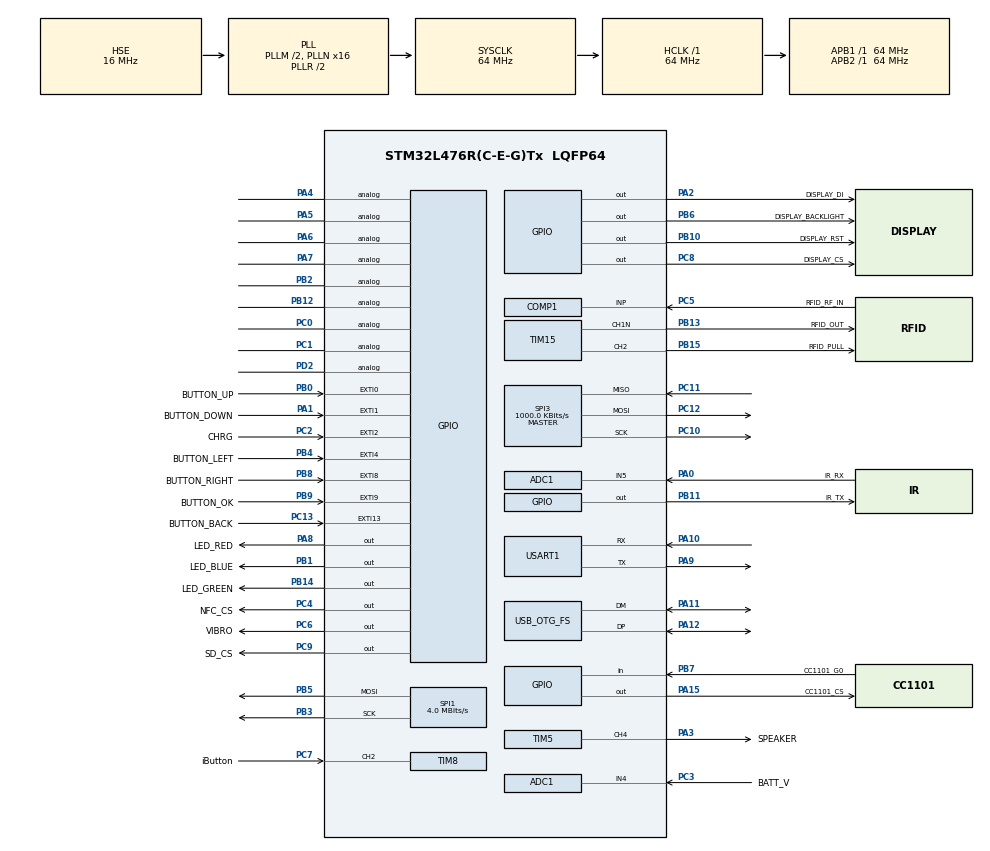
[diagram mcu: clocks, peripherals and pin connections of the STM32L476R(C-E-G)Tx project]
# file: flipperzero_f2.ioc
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ADC1.Channel-0\#ChannelRegularConversion=ADC_CHANNEL_4
ADC1.NbrOfConversion=1
ADC1.NbrOfConversionFlag=1
ADC1.OffsetNumber-0\#ChannelRegularConversion=ADC_OFFSET_NONE
ADC1.Rank-0\#ChannelRegularConversion=1
ADC1.SamplingTime-0\#ChannelRegularConversion=ADC_SAMPLETIME_2CYCLES_5
ADC1.master=1
FREERTOS.HEAP_NUMBER=1
FREERTOS.Tasks01=defaultTask,0,1024,StartDefaultTask,Default,NULL,Dynamic,NULL,NULL
FREERTOS.configTOTAL_HEAP_SIZE=8192
FREERTOS.configUSE_IDLE_HOOK=1
FREERTOS.configUSE_TIMERS=1
Mcu.Family=STM32L4
Mcu.Name=STM32L476R(C-E-G)Tx
Mcu.Package=LQFP64
NVIC.EXTI0_IRQn=true\:5\:0\:false\:false\:true\:true\:true\:true
NVIC.EXTI15_10_IRQn=true\:5\:0\:true\:false\:true\:false\:true\:true
NVIC.EXTI1_IRQn=true\:5\:0\:false\:false\:true\:true\:true\:true
NVIC.EXTI2_IRQn=true\:5\:0\:false\:false\:true\:true\:true\:true
NVIC.EXTI4_IRQn=true\:5\:0\:false\:false\:true\:true\:true\:true
NVIC.EXTI9_5_IRQn=true\:5\:0\:false\:false\:true\:true\:true\:true
NVIC.OTG_FS_IRQn=true\:5\:0\:false\:false\:true\:true\:false\:true
NVIC.PriorityGroup=NVIC_PRIORITYGROUP_4
NVIC.TIM8_CC_IRQn=true\:5\:0\:false\:false\:true\:true\:true\:true
PA0.GPIO_Label=IR_RX
PA0.Signal=ADCx_IN5
PA1.GPIO_Label=BUTTON_DOWN
PA1.GPIO_ModeDefaultEXTI=GPIO_MODE_IT_RISING_FALLING
PA1.GPIO_PuPd=GPIO_PULLDOWN
PA1.Signal=GPXTI1
PA10.Mode=Asynchronous
PA10.Signal=USART1_RX
PA11.Mode=Device_Only
PA11.Signal=USB_OTG_FS_DM
PA12.Mode=Device_Only
PA12.Signal=USB_OTG_FS_DP
PA13\ (JTMS-SWDIO).GPIO_Label=TMS
PA13\ (JTMS-SWDIO).Mode=Serial_Wire
PA13\ (JTMS-SWDIO).Signal=SYS_JTMS-SWDIO
PA14\ (JTCK-SWCLK).GPIO_Label=TCK
PA14\ (JTCK-SWCLK).Mode=Serial_Wire
PA14\ (JTCK-SWCLK).Signal=SYS_JTCK-SWCLK
PA15\ (JTDI).GPIO_Label=CC1101_CS
PA15\ (JTDI).Signal=GPIO_Output
PA2.GPIO_Label=DISPLAY_DI
PA2.Signal=GPIO_Output
PA3.GPIO_Label=SPEAKER
PA3.Signal=S_TIM5_CH4
PA4.Signal=GPIO_Analog
PA5.Signal=GPIO_Analog
PA6.Signal=GPIO_Analog
PA7.Signal=GPIO_Analog
PA8.GPIO_Label=LED_RED
PA8.GPIO_ModeDefaultOutputPP=GPIO_MODE_OUTPUT_OD
PA8.GPIO_Speed=GPIO_SPEED_FREQ_HIGH
PA8.PinState=GPIO_PIN_SET
PA8.Signal=GPIO_Output
PA9.Mode=Asynchronous
PA9.Signal=USART1_TX
PB0.GPIO_Label=BUTTON_UP
PB0.GPIO_ModeDefaultEXTI=GPIO_MODE_IT_RISING_FALLING
PB0.GPIO_PuPd=GPIO_PULLDOWN
PB0.Signal=GPXTI0
PB1.GPIO_Label=LED_BLUE
PB1.GPIO_ModeDefaultOutputPP=GPIO_MODE_OUTPUT_OD
PB1.GPIO_Speed=GPIO_SPEED_FREQ_MEDIUM
PB1.PinState=GPIO_PIN_SET
PB1.Signal=GPIO_Output
PB10.GPIO_Label=DISPLAY_RST
PB10.Signal=GPIO_Output
PB11.GPIO_Label=IR_TX
PB11.Signal=GPIO_Output
PB12.Signal=GPIO_Analog
PB13.GPIO_Label=RFID_OUT
PB13.Mode=Output Compare1 CH1N
PB13.Signal=TIM15_CH1N
PB14.GPIO_Label=LED_GREEN
PB14.GPIO_ModeDefaultOutputPP=GPIO_MODE_OUTPUT_OD
PB14.GPIO_Speed=GPIO_SPEED_FREQ_MEDIUM
PB14.PinState=GPIO_PIN_SET
PB14.Signal=GPIO_Output
PB15.GPIO_Label=RFID_PULL
PB15.Signal=S_TIM15_CH2
PB2.Signal=GPIO_Analog
PB3\ (JTDO-TRACESWO).Mode=TX_Only_Simplex_Unidirect_Master
PB3\ (JTDO-TRACESWO).Signal=SPI1_SCK
PB4\ (NJTRST).GPIO_Label=BUTTON_LEFT
PB4\ (NJTRST).GPIO_ModeDefaultEXTI=GPIO_MODE_IT_RISING_FALLING
PB4\ (NJTRST).GPIO_PuPd=GPIO_PULLDOWN
PB4\ (NJTRST).Signal=GPXTI4
PB5.Mode=TX_Only_Simplex_Unidirect_Master
PB5.Signal=SPI1_MOSI
PB6.GPIO_Label=DISPLAY_BACKLIGHT
PB6.GPIO_Speed=GPIO_SPEED_FREQ_LOW
PB6.Signal=GPIO_Output
PB7.GPIO_Label=CC1101_G0
PB7.Signal=GPIO_Input
PB8.GPIO_Label=BUTTON_RIGHT
PB8.GPIO_ModeDefaultEXTI=GPIO_MODE_IT_RISING_FALLING
PB8.GPIO_PuPd=GPIO_PULLDOWN
PB8.Signal=GPXTI8
PB9.GPIO_Label=BUTTON_OK
PB9.GPIO_ModeDefaultEXTI=GPIO_MODE_IT_RISING_FALLING
PB9.GPIO_PuPd=GPIO_PULLDOWN
PB9.Signal=GPXTI9
PC0.Signal=GPIO_Analog
PC1.Signal=GPIO_Analog
PC10.Mode=Full_Duplex_Master
PC10.Signal=SPI3_SCK
PC11.Mode=Full_Duplex_Master
PC11.Signal=SPI3_MISO
PC12.Mode=Full_Duplex_Master
PC12.Signal=SPI3_MOSI
PC13.GPIO_Label=BUTTON_BACK
PC13.GPIO_ModeDefaultEXTI=GPIO_MODE_IT_RISING_FALLING
PC13.GPIO_PuPd=GPIO_PULLDOWN
PC13.Signal=GPXTI13
PC14-OSC32_IN\ (PC14).Mode=LSE-External-Oscillator
PC14-OSC32_IN\ (PC14).Signal=RCC_OSC32_IN
PC15-OSC32_OUT\ (PC15).Mode=LSE-External-Oscillator
PC15-OSC32_OUT\ (PC15).Signal=RCC_OSC32_OUT
PC2.GPIO_Label=CHRG
PC2.GPIO_ModeDefaultEXTI=GPIO_MODE_IT_RISING_FALLING
PC2.GPIO_PuPd=GPIO_PULLUP
PC2.Signal=GPXTI2
PC3.GPIO_Label=BATT_V
PC3.Signal=ADCx_IN4
PC4.GPIO_Label=NFC_CS
PC4.Signal=GPIO_Output
PC5.GPIO_Label=RFID_RF_IN
PC5.Mode=INP
PC5.Signal=COMP1_INP
PC6.GPIO_Label=VIBRO
PC6.Signal=GPIO_Output
PC7.GPIO_Label=iButton
PC7.GPIO_ModeDefaultPP=GPIO_MODE_AF_OD
PC7.GPIO_PuPd=GPIO_NOPULL
PC7.GPIO_Speed=GPIO_SPEED_FREQ_MEDIUM
PC7.Signal=S_TIM8_CH2
PC8.GPIO_Label=DISPLAY_CS
PC8.Signal=GPIO_Output
PC9.GPIO_Label=SD_CS
PC9.Signal=GPIO_Output
PD2.Signal=GPIO_Analog
PH0-OSC_IN\ (PH0).Mode=HSE-External-Oscillator
PH0-OSC_IN\ (PH0).Signal=RCC_OSC_IN
PH1-OSC_OUT\ (PH1).Mode=HSE-External-Oscillator
PH1-OSC_OUT\ (PH1).Signal=RCC_OSC_OUT
ProjectManager.HeapSize=0x200
ProjectManager.StackSize=0x400
ProjectManager.TargetToolchain=Makefile
RCC.ADCCLockSelection=RCC_ADCCLKSOURCE_SYSCLK
RCC.ADCFreq_Value=64000000
RCC.AHBFreq_Value=64000000
RCC.APB1Freq_Value=64000000
RCC.APB1TimFreq_Value=64000000
RCC.APB2Freq_Value=64000000
RCC.APB2TimFreq_Value=64000000
RCC.CortexFreq_Value=64000000
RCC.HCLKFreq_Value=64000000
RCC.HSE_VALUE=16000000
RCC.HSI_VALUE=16000000
RCC.MSI_VALUE=4000000
RCC.PLLM=2
RCC.PLLN=16
RCC.PLLSAI1N=12
RCC.PLLSourceVirtual=RCC_PLLSOURCE_HSE
RCC.PREFETCH_ENABLE=1
RCC.SYSCLKFreq_VALUE=64000000
RCC.SYSCLKSource=RCC_SYSCLKSOURCE_PLLCLK
RCC.USBFreq_Value=48000000
RCC.VCOOutputFreq_Value=128000000
SH.ADCx_IN4.0=ADC1_IN4,IN4-Single-Ended
SH.ADCx_IN5.0=ADC1_IN5,IN5-Single-Ended
SH.S_TIM15_CH2.0=TIM15_CH2,Output Compare2 CH2
SH.S_TIM5_CH4.0=TIM5_CH4,PWM Generation4 CH4
SH.S_TIM8_CH2.0=TIM8_CH2,Input_Capture2_from_TI2
SPI1.BaudRatePrescaler=SPI_BAUDRATEPRESCALER_16
SPI1.CLKPhase=SPI_PHASE_1EDGE
SPI1.CLKPolarity=SPI_POLARITY_LOW
SPI1.CalculateBaudRate=4.0 MBits/s
SPI1.DataSize=SPI_DATASIZE_8BIT
SPI1.Direction=SPI_DIRECTION_2LINES
SPI1.Mode=SPI_MODE_MASTER
SPI1.VirtualType=VM_MASTER
SPI3.BaudRatePrescaler=SPI_BAUDRATEPRESCALER_64
SPI3.CLKPolarity=SPI_POLARITY_LOW
SPI3.CalculateBaudRate=1000.0 KBits/s
SPI3.DataSize=SPI_DATASIZE_8BIT
SPI3.Direction=SPI_DIRECTION_2LINES
SPI3.Mode=SPI_MODE_MASTER
SPI3.VirtualType=VM_MASTER
TIM15.Channel-Output\ Compare1\ CH1N=TIM_CHANNEL_1
TIM15.Channel-Output\ Compare2\ CH2=TIM_CHANNEL_2
TIM5.Channel-PWM\ Generation4\ CH4=TIM_CHANNEL_4
TIM5.Period=291
TIM5.Prescaler=500 - 1
TIM5.Pulse-PWM\ Generation4\ CH4=145
TIM8.Channel-Input_Capture2_from_TI2=TIM_CHANNEL_2
TIM8.ICPolarity_CH2=TIM_INPUTCHANNELPOLARITY_BOTHEDGE
TIM8.Period=32768-1
TIM8.Prescaler=64-1
USART1.VirtualMode-Asynchronous=VM_ASYNC
USB_DEVICE.CLASS_NAME_FS=CDC
USB_DEVICE.VirtualMode=Cdc
USB_DEVICE.VirtualModeFS=Cdc_FS
USB_OTG_FS.VirtualMode=Device_Only
VP_ADC1_TempSens_Input.Mode=IN-TempSens
VP_ADC1_Vref_Input.Mode=IN-Vrefint
VP_COMP1_VS_VREFINT12.Mode=VREFINT_12
VP_FREERTOS_VS_CMSIS_V1.Mode=CMSIS_V1
VP_TIM8_VS_ClockSourceINT.Mode=Internal
VP_USB_DEVICE_VS_USB_DEVICE_CDC_FS.Mode=CDC_FS
board=NUCLEO-L476RG

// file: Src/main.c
/* USER CODE BEGIN Header */
/**
  ******************************************************************************
  * @file           : main.c
  * @brief          : Main program body
  ******************************************************************************
  * @attention
  *
  * <h2><center>&copy; Copyright (c) 2020 STMicroelectronics.
  * All rights reserved.</center></h2>
  *
  * This software component is licensed by ST under Ultimate Liberty license
  * SLA0044, the "License"; You may not use this file except in compliance with
  * the License. You may obtain a copy of the License at:
  *                             www.st.com/SLA0044
  *
  ******************************************************************************
  */
/* USER CODE END Header */

#include "main.h"
#include "boot.h"
#include "cmsis_os.h"
#include "usb_device.h"

ADC_HandleTypeDef hadc1;

COMP_HandleTypeDef hcomp1;

SPI_HandleTypeDef hspi1;
SPI_HandleTypeDef hspi3;

TIM_HandleTypeDef htim5;
TIM_HandleTypeDef htim8;
TIM_HandleTypeDef htim15;

UART_HandleTypeDef huart1;

osThreadId defaultTaskHandle;

void SystemClock_Config(void);
static void MX_GPIO_Init(void);
static void MX_SPI1_Init(void);
static void MX_SPI3_Init(void);
static void MX_ADC1_Init(void);
static void MX_COMP1_Init(void);
static void MX_TIM5_Init(void);
static void MX_TIM15_Init(void);
static void MX_USART1_UART_Init(void);
static void MX_TIM8_Init(void);
void StartDefaultTask(void const* argument);

int main(void) {

    /* MCU Configuration--------------------------------------------------------*/

    /* Reset of all peripherals, Initializes the Flash interface and the Systick. */
    HAL_Init();

    /* Configure the system clock */
    SystemClock_Config();

    /* Initialize all configured peripherals */
    MX_GPIO_Init();
    MX_SPI1_Init();
    MX_SPI3_Init();
    MX_ADC1_Init();
    MX_COMP1_Init();
    MX_TIM5_Init();
    MX_TIM15_Init();
    MX_USART1_UART_Init();
    MX_TIM8_Init();

    /* Create the thread(s) */
    /* definition and creation of defaultTask */
    osThreadDef(defaultTask, StartDefaultTask, osPriorityNormal, 0, 1024);
    defaultTaskHandle = osThreadCreate(osThread(defaultTask), NULL);

    /* Start scheduler */
    osKernelStart();

    /* We should never get here as control is now taken by the scheduler */

    /* Infinite loop */
    while(1) {

    }
}

void SystemClock_Config(void) {
    RCC_OscInitTypeDef RCC_OscInitStruct = {0};
    RCC_ClkInitTypeDef RCC_ClkInitStruct = {0};
    RCC_PeriphCLKInitTypeDef PeriphClkInit = {0};

    /** Initializes the CPU, AHB and APB busses clocks
  */
    RCC_OscInitStruct.OscillatorType = RCC_OSCILLATORTYPE_HSE;
    RCC_OscInitStruct.HSEState = RCC_HSE_ON;
    RCC_OscInitStruct.PLL.PLLState = RCC_PLL_ON;
    RCC_OscInitStruct.PLL.PLLSource = RCC_PLLSOURCE_HSE;
    RCC_OscInitStruct.PLL.PLLM = 2;
    RCC_OscInitStruct.PLL.PLLN = 16;
    RCC_OscInitStruct.PLL.PLLP = RCC_PLLP_DIV7;
    RCC_OscInitStruct.PLL.PLLQ = RCC_PLLQ_DIV2;
    RCC_OscInitStruct.PLL.PLLR = RCC_PLLR_DIV2;
    if(HAL_RCC_OscConfig(&RCC_OscInitStruct) != HAL_OK) {
        Error_Handler();
    }
    /** Initializes the CPU, AHB and APB busses clocks
  */
    RCC_ClkInitStruct.ClockType = RCC_CLOCKTYPE_HCLK | RCC_CLOCKTYPE_SYSCLK | RCC_CLOCKTYPE_PCLK1 |
                                  RCC_CLOCKTYPE_PCLK2;
    RCC_ClkInitStruct.SYSCLKSource = RCC_SYSCLKSOURCE_PLLCLK;
    RCC_ClkInitStruct.AHBCLKDivider = RCC_SYSCLK_DIV1;
    RCC_ClkInitStruct.APB1CLKDivider = RCC_HCLK_DIV1;
    RCC_ClkInitStruct.APB2CLKDivider = RCC_HCLK_DIV1;

    if(HAL_RCC_ClockConfig(&RCC_ClkInitStruct, FLASH_LATENCY_3) != HAL_OK) {
        Error_Handler();
    }
    PeriphClkInit.PeriphClockSelection = RCC_PERIPHCLK_USART1 | RCC_PERIPHCLK_USB |
                                         RCC_PERIPHCLK_ADC;
    PeriphClkInit.Usart1ClockSelection = RCC_USART1CLKSOURCE_PCLK2;
    PeriphClkInit.AdcClockSelection = RCC_ADCCLKSOURCE_SYSCLK;
    PeriphClkInit.UsbClockSelection = RCC_USBCLKSOURCE_PLLSAI1;
    PeriphClkInit.PLLSAI1.PLLSAI1Source = RCC_PLLSOURCE_HSE;
    PeriphClkInit.PLLSAI1.PLLSAI1M = 2;
    PeriphClkInit.PLLSAI1.PLLSAI1N = 12;
    PeriphClkInit.PLLSAI1.PLLSAI1P = RCC_PLLP_DIV7;
    PeriphClkInit.PLLSAI1.PLLSAI1Q = RCC_PLLQ_DIV2;
    PeriphClkInit.PLLSAI1.PLLSAI1R = RCC_PLLR_DIV2;
    PeriphClkInit.PLLSAI1.PLLSAI1ClockOut = RCC_PLLSAI1_48M2CLK;
    if(HAL_RCCEx_PeriphCLKConfig(&PeriphClkInit) != HAL_OK) {
        Error_Handler();
    }
    /** Configure the main internal regulator output voltage
  */
    if(HAL_PWREx_ControlVoltageScaling(PWR_REGULATOR_VOLTAGE_SCALE1) != HAL_OK) {
        Error_Handler();
    }
}

static void MX_ADC1_Init(void) {

    ADC_MultiModeTypeDef multimode = {0};
    ADC_ChannelConfTypeDef sConfig = {0};

    /** Common config
  */
    hadc1.Instance = ADC1;
    hadc1.Init.ClockPrescaler = ADC_CLOCK_ASYNC_DIV1;
    hadc1.Init.Resolution = ADC_RESOLUTION_12B;
    hadc1.Init.DataAlign = ADC_DATAALIGN_RIGHT;
    hadc1.Init.ScanConvMode = ADC_SCAN_DISABLE;
    hadc1.Init.EOCSelection = ADC_EOC_SINGLE_CONV;
    hadc1.Init.LowPowerAutoWait = DISABLE;
    hadc1.Init.ContinuousConvMode = DISABLE;
    hadc1.Init.NbrOfConversion = 1;
    hadc1.Init.DiscontinuousConvMode = DISABLE;
    hadc1.Init.ExternalTrigConv = ADC_SOFTWARE_START;
    hadc1.Init.ExternalTrigConvEdge = ADC_EXTERNALTRIGCONVEDGE_NONE;
    hadc1.Init.DMAContinuousRequests = DISABLE;
    hadc1.Init.Overrun = ADC_OVR_DATA_PRESERVED;
    hadc1.Init.OversamplingMode = DISABLE;
    if(HAL_ADC_Init(&hadc1) != HAL_OK) {
        Error_Handler();
    }
    /** Configure the ADC multi-mode
  */
    multimode.Mode = ADC_MODE_INDEPENDENT;
    if(HAL_ADCEx_MultiModeConfigChannel(&hadc1, &multimode) != HAL_OK) {
        Error_Handler();
    }
    /** Configure Regular Channel
  */
    sConfig.Channel = ADC_CHANNEL_4;
    sConfig.Rank = ADC_REGULAR_RANK_1;
    sConfig.SamplingTime = ADC_SAMPLETIME_2CYCLES_5;
    sConfig.SingleDiff = ADC_SINGLE_ENDED;
    sConfig.OffsetNumber = ADC_OFFSET_NONE;
    sConfig.Offset = 0;
    if(HAL_ADC_ConfigChannel(&hadc1, &sConfig) != HAL_OK) {
        Error_Handler();
    }
}

static void MX_COMP1_Init(void) {

    hcomp1.Instance = COMP1;
    hcomp1.Init.InvertingInput = COMP_INPUT_MINUS_1_2VREFINT;
    hcomp1.Init.NonInvertingInput = COMP_INPUT_PLUS_IO1;
    hcomp1.Init.OutputPol = COMP_OUTPUTPOL_NONINVERTED;
    hcomp1.Init.Hysteresis = COMP_HYSTERESIS_NONE;
    hcomp1.Init.BlankingSrce = COMP_BLANKINGSRC_NONE;
    hcomp1.Init.Mode = COMP_POWERMODE_HIGHSPEED;
    hcomp1.Init.WindowMode = COMP_WINDOWMODE_DISABLE;
    hcomp1.Init.TriggerMode = COMP_TRIGGERMODE_NONE;
    if(HAL_COMP_Init(&hcomp1) != HAL_OK) {
        Error_Handler();
    }
}

static void MX_SPI1_Init(void) {

    /* SPI1 parameter configuration*/
    hspi1.Instance = SPI1;
    hspi1.Init.Mode = SPI_MODE_MASTER;
    hspi1.Init.Direction = SPI_DIRECTION_2LINES;
    hspi1.Init.DataSize = SPI_DATASIZE_8BIT;
    hspi1.Init.CLKPolarity = SPI_POLARITY_LOW;
    hspi1.Init.CLKPhase = SPI_PHASE_1EDGE;
    hspi1.Init.NSS = SPI_NSS_SOFT;
    hspi1.Init.BaudRatePrescaler = SPI_BAUDRATEPRESCALER_16;
    hspi1.Init.FirstBit = SPI_FIRSTBIT_MSB;
    hspi1.Init.TIMode = SPI_TIMODE_DISABLE;
    hspi1.Init.CRCCalculation = SPI_CRCCALCULATION_DISABLE;
    hspi1.Init.CRCPolynomial = 7;
    hspi1.Init.CRCLength = SPI_CRC_LENGTH_DATASIZE;
    hspi1.Init.NSSPMode = SPI_NSS_PULSE_ENABLE;
    if(HAL_SPI_Init(&hspi1) != HAL_OK) {
        Error_Handler();
    }
}

static void MX_SPI3_Init(void) {

    /* SPI3 parameter configuration*/
    hspi3.Instance = SPI3;
    hspi3.Init.Mode = SPI_MODE_MASTER;
    hspi3.Init.Direction = SPI_DIRECTION_2LINES;
    hspi3.Init.DataSize = SPI_DATASIZE_8BIT;
    hspi3.Init.CLKPolarity = SPI_POLARITY_LOW;
    hspi3.Init.CLKPhase = SPI_PHASE_1EDGE;
    hspi3.Init.NSS = SPI_NSS_SOFT;
    hspi3.Init.BaudRatePrescaler = SPI_BAUDRATEPRESCALER_64;
    hspi3.Init.FirstBit = SPI_FIRSTBIT_MSB;
    hspi3.Init.TIMode = SPI_TIMODE_DISABLE;
    hspi3.Init.CRCCalculation = SPI_CRCCALCULATION_DISABLE;
    hspi3.Init.CRCPolynomial = 7;
    hspi3.Init.CRCLength = SPI_CRC_LENGTH_DATASIZE;
    hspi3.Init.NSSPMode = SPI_NSS_PULSE_ENABLE;
    if(HAL_SPI_Init(&hspi3) != HAL_OK) {
        Error_Handler();
    }
}

static void MX_TIM5_Init(void) {

    TIM_MasterConfigTypeDef sMasterConfig = {0};
    TIM_OC_InitTypeDef sConfigOC = {0};

    htim5.Instance = TIM5;
    htim5.Init.Prescaler = 500 - 1;
    htim5.Init.CounterMode = TIM_COUNTERMODE_UP;
    htim5.Init.Period = 291;
    htim5.Init.ClockDivision = TIM_CLOCKDIVISION_DIV1;
    htim5.Init.AutoReloadPreload = TIM_AUTORELOAD_PRELOAD_DISABLE;
    if(HAL_TIM_PWM_Init(&htim5) != HAL_OK) {
        Error_Handler();
    }
    sMasterConfig.MasterOutputTrigger = TIM_TRGO_RESET;
    sMasterConfig.MasterSlaveMode = TIM_MASTERSLAVEMODE_DISABLE;
    if(HAL_TIMEx_MasterConfigSynchronization(&htim5, &sMasterConfig) != HAL_OK) {
        Error_Handler();
    }
    sConfigOC.OCMode = TIM_OCMODE_PWM1;
    sConfigOC.Pulse = 145;
    sConfigOC.OCPolarity = TIM_OCPOLARITY_HIGH;
    sConfigOC.OCFastMode = TIM_OCFAST_DISABLE;
    if(HAL_TIM_PWM_ConfigChannel(&htim5, &sConfigOC, TIM_CHANNEL_4) != HAL_OK) {
        Error_Handler();
    }
    HAL_TIM_MspPostInit(&htim5);
}

static void MX_TIM8_Init(void) {

    TIM_ClockConfigTypeDef sClockSourceConfig = {0};
    TIM_MasterConfigTypeDef sMasterConfig = {0};
    TIM_IC_InitTypeDef sConfigIC = {0};

    htim8.Instance = TIM8;
    htim8.Init.Prescaler = 64 - 1;
    htim8.Init.CounterMode = TIM_COUNTERMODE_UP;
    htim8.Init.Period = 32768 - 1;
    htim8.Init.ClockDivision = TIM_CLOCKDIVISION_DIV1;
    htim8.Init.RepetitionCounter = 0;
    htim8.Init.AutoReloadPreload = TIM_AUTORELOAD_PRELOAD_DISABLE;
    if(HAL_TIM_Base_Init(&htim8) != HAL_OK) {
        Error_Handler();
    }
    sClockSourceConfig.ClockSource = TIM_CLOCKSOURCE_INTERNAL;
    if(HAL_TIM_ConfigClockSource(&htim8, &sClockSourceConfig) != HAL_OK) {
        Error_Handler();
    }
    if(HAL_TIM_IC_Init(&htim8) != HAL_OK) {
        Error_Handler();
    }
    sMasterConfig.MasterOutputTrigger = TIM_TRGO_RESET;
    sMasterConfig.MasterOutputTrigger2 = TIM_TRGO2_RESET;
    sMasterConfig.MasterSlaveMode = TIM_MASTERSLAVEMODE_DISABLE;
    if(HAL_TIMEx_MasterConfigSynchronization(&htim8, &sMasterConfig) != HAL_OK) {
        Error_Handler();
    }
    sConfigIC.ICPolarity = TIM_INPUTCHANNELPOLARITY_BOTHEDGE;
    sConfigIC.ICSelection = TIM_ICSELECTION_DIRECTTI;
    sConfigIC.ICPrescaler = TIM_ICPSC_DIV1;
    sConfigIC.ICFilter = 0;
    if(HAL_TIM_IC_ConfigChannel(&htim8, &sConfigIC, TIM_CHANNEL_2) != HAL_OK) {
        Error_Handler();
    }
}

static void MX_TIM15_Init(void) {

    TIM_MasterConfigTypeDef sMasterConfig = {0};
    TIM_OC_InitTypeDef sConfigOC = {0};
    TIM_BreakDeadTimeConfigTypeDef sBreakDeadTimeConfig = {0};

    htim15.Instance = TIM15;
    htim15.Init.Prescaler = 0;
    htim15.Init.CounterMode = TIM_COUNTERMODE_UP;
    htim15.Init.Period = 0;
    htim15.Init.ClockDivision = TIM_CLOCKDIVISION_DIV1;
    htim15.Init.RepetitionCounter = 0;
    htim15.Init.AutoReloadPreload = TIM_AUTORELOAD_PRELOAD_DISABLE;
    if(HAL_TIM_OC_Init(&htim15) != HAL_OK) {
        Error_Handler();
    }
    sMasterConfig.MasterOutputTrigger = TIM_TRGO_RESET;
    sMasterConfig.MasterSlaveMode = TIM_MASTERSLAVEMODE_DISABLE;
    if(HAL_TIMEx_MasterConfigSynchronization(&htim15, &sMasterConfig) != HAL_OK) {
        Error_Handler();
    }
    sConfigOC.OCMode = TIM_OCMODE_TIMING;
    sConfigOC.Pulse = 0;
    sConfigOC.OCPolarity = TIM_OCPOLARITY_HIGH;
    sConfigOC.OCNPolarity = TIM_OCNPOLARITY_HIGH;
    sConfigOC.OCFastMode = TIM_OCFAST_DISABLE;
    sConfigOC.OCIdleState = TIM_OCIDLESTATE_RESET;
    sConfigOC.OCNIdleState = TIM_OCNIDLESTATE_RESET;
    if(HAL_TIM_OC_ConfigChannel(&htim15, &sConfigOC, TIM_CHANNEL_1) != HAL_OK) {
        Error_Handler();
    }
    if(HAL_TIM_OC_ConfigChannel(&htim15, &sConfigOC, TIM_CHANNEL_2) != HAL_OK) {
        Error_Handler();
    }
    sBreakDeadTimeConfig.OffStateRunMode = TIM_OSSR_DISABLE;
    sBreakDeadTimeConfig.OffStateIDLEMode = TIM_OSSI_DISABLE;
    sBreakDeadTimeConfig.LockLevel = TIM_LOCKLEVEL_OFF;
    sBreakDeadTimeConfig.DeadTime = 0;
    sBreakDeadTimeConfig.BreakState = TIM_BREAK_DISABLE;
    sBreakDeadTimeConfig.BreakPolarity = TIM_BREAKPOLARITY_HIGH;
    sBreakDeadTimeConfig.AutomaticOutput = TIM_AUTOMATICOUTPUT_DISABLE;
    if(HAL_TIMEx_ConfigBreakDeadTime(&htim15, &sBreakDeadTimeConfig) != HAL_OK) {
        Error_Handler();
    }
    HAL_TIM_MspPostInit(&htim15);
}

static void MX_USART1_UART_Init(void) {

    huart1.Instance = USART1;
    huart1.Init.BaudRate = 115200;
    huart1.Init.WordLength = UART_WORDLENGTH_8B;
    huart1.Init.StopBits = UART_STOPBITS_1;
    huart1.Init.Parity = UART_PARITY_NONE;
    huart1.Init.Mode = UART_MODE_TX_RX;
    huart1.Init.HwFlowCtl = UART_HWCONTROL_NONE;
    huart1.Init.OverSampling = UART_OVERSAMPLING_16;
    huart1.Init.OneBitSampling = UART_ONE_BIT_SAMPLE_DISABLE;
    huart1.AdvancedInit.AdvFeatureInit = UART_ADVFEATURE_NO_INIT;
    if(HAL_UART_Init(&huart1) != HAL_OK) {
        Error_Handler();
    }
}

static void MX_GPIO_Init(void) {
    GPIO_InitTypeDef GPIO_InitStruct = {0};

    /* GPIO Ports Clock Enable */
    __HAL_RCC_GPIOC_CLK_ENABLE();
    __HAL_RCC_GPIOH_CLK_ENABLE();
    __HAL_RCC_GPIOA_CLK_ENABLE();
    __HAL_RCC_GPIOB_CLK_ENABLE();
    __HAL_RCC_GPIOD_CLK_ENABLE();

    /*Configure GPIO pin Output Level */
    HAL_GPIO_WritePin(GPIOA, DISPLAY_DI_Pin | CC1101_CS_Pin, GPIO_PIN_RESET);

    /*Configure GPIO pin Output Level */
    HAL_GPIO_WritePin(GPIOC, NFC_CS_Pin | VIBRO_Pin | DISPLAY_CS_Pin | SD_CS_Pin, GPIO_PIN_RESET);

    /*Configure GPIO pin Output Level */
    HAL_GPIO_WritePin(GPIOB, LED_BLUE_Pin | LED_GREEN_Pin, GPIO_PIN_SET);

    /*Configure GPIO pin Output Level */
    HAL_GPIO_WritePin(GPIOB, DISPLAY_RST_Pin | IR_TX_Pin | DISPLAY_BACKLIGHT_Pin, GPIO_PIN_RESET);

    /*Configure GPIO pin Output Level */
    HAL_GPIO_WritePin(LED_RED_GPIO_Port, LED_RED_Pin, GPIO_PIN_SET);

    /*Configure GPIO pin : BUTTON_BACK_Pin */
    GPIO_InitStruct.Pin = BUTTON_BACK_Pin;
    GPIO_InitStruct.Mode = GPIO_MODE_IT_RISING_FALLING;
    GPIO_InitStruct.Pull = GPIO_PULLDOWN;
    HAL_GPIO_Init(BUTTON_BACK_GPIO_Port, &GPIO_InitStruct);

    /*Configure GPIO pins : PC0 PC1 */
    GPIO_InitStruct.Pin = GPIO_PIN_0 | GPIO_PIN_1;
    GPIO_InitStruct.Mode = GPIO_MODE_ANALOG;
    GPIO_InitStruct.Pull = GPIO_NOPULL;
    HAL_GPIO_Init(GPIOC, &GPIO_InitStruct);

    /*Configure GPIO pin : CHRG_Pin */
    GPIO_InitStruct.Pin = CHRG_Pin;
    GPIO_InitStruct.Mode = GPIO_MODE_IT_RISING_FALLING;
    GPIO_InitStruct.Pull = GPIO_PULLUP;
    HAL_GPIO_Init(CHRG_GPIO_Port, &GPIO_InitStruct);

    /*Configure GPIO pin : BUTTON_DOWN_Pin */
    GPIO_InitStruct.Pin = BUTTON_DOWN_Pin;
    GPIO_InitStruct.Mode = GPIO_MODE_IT_RISING_FALLING;
    GPIO_InitStruct.Pull = GPIO_PULLDOWN;
    HAL_GPIO_Init(BUTTON_DOWN_GPIO_Port, &GPIO_InitStruct);

    /*Configure GPIO pins : DISPLAY_DI_Pin CC1101_CS_Pin */
    GPIO_InitStruct.Pin = DISPLAY_DI_Pin | CC1101_CS_Pin;
    GPIO_InitStruct.Mode = GPIO_MODE_OUTPUT_PP;
    GPIO_InitStruct.Pull = GPIO_NOPULL;
    GPIO_InitStruct.Speed = GPIO_SPEED_FREQ_LOW;
    HAL_GPIO_Init(GPIOA, &GPIO_InitStruct);

    /*Configure GPIO pins : PA4 PA5 PA6 PA7 */
    GPIO_InitStruct.Pin = GPIO_PIN_4 | GPIO_PIN_5 | GPIO_PIN_6 | GPIO_PIN_7;
    GPIO_InitStruct.Mode = GPIO_MODE_ANALOG;
    GPIO_InitStruct.Pull = GPIO_NOPULL;
    HAL_GPIO_Init(GPIOA, &GPIO_InitStruct);

    /*Configure GPIO pins : NFC_CS_Pin VIBRO_Pin DISPLAY_CS_Pin SD_CS_Pin */
    GPIO_InitStruct.Pin = NFC_CS_Pin | VIBRO_Pin | DISPLAY_CS_Pin | SD_CS_Pin;
    GPIO_InitStruct.Mode = GPIO_MODE_OUTPUT_PP;
    GPIO_InitStruct.Pull = GPIO_NOPULL;
    GPIO_InitStruct.Speed = GPIO_SPEED_FREQ_LOW;
    HAL_GPIO_Init(GPIOC, &GPIO_InitStruct);

    /*Configure GPIO pins : BUTTON_UP_Pin BUTTON_RIGHT_Pin BUTTON_OK_Pin */
    GPIO_InitStruct.Pin = BUTTON_UP_Pin | BUTTON_RIGHT_Pin | BUTTON_OK_Pin;
    GPIO_InitStruct.Mode = GPIO_MODE_IT_RISING_FALLING;
    GPIO_InitStruct.Pull = GPIO_PULLDOWN;
    HAL_GPIO_Init(GPIOB, &GPIO_InitStruct);

    /*Configure GPIO pins : LED_BLUE_Pin LED_GREEN_Pin */
    GPIO_InitStruct.Pin = LED_BLUE_Pin | LED_GREEN_Pin;
    GPIO_InitStruct.Mode = GPIO_MODE_OUTPUT_OD;
    GPIO_InitStruct.Pull = GPIO_NOPULL;
    GPIO_InitStruct.Speed = GPIO_SPEED_FREQ_MEDIUM;
    HAL_GPIO_Init(GPIOB, &GPIO_InitStruct);

    /*Configure GPIO pins : PB2 PB12 */
    GPIO_InitStruct.Pin = GPIO_PIN_2 | GPIO_PIN_12;
    GPIO_InitStruct.Mode = GPIO_MODE_ANALOG;
    GPIO_InitStruct.Pull = GPIO_NOPULL;
    HAL_GPIO_Init(GPIOB, &GPIO_InitStruct);

    /*Configure GPIO pins : DISPLAY_RST_Pin IR_TX_Pin DISPLAY_BACKLIGHT_Pin */
    GPIO_InitStruct.Pin = DISPLAY_RST_Pin | IR_TX_Pin | DISPLAY_BACKLIGHT_Pin;
    GPIO_InitStruct.Mode = GPIO_MODE_OUTPUT_PP;
    GPIO_InitStruct.Pull = GPIO_NOPULL;
    GPIO_InitStruct.Speed = GPIO_SPEED_FREQ_LOW;
    HAL_GPIO_Init(GPIOB, &GPIO_InitStruct);

    /*Configure GPIO pin : LED_RED_Pin */
    GPIO_InitStruct.Pin = LED_RED_Pin;
    GPIO_InitStruct.Mode = GPIO_MODE_OUTPUT_OD;
    GPIO_InitStruct.Pull = GPIO_NOPULL;
    GPIO_InitStruct.Speed = GPIO_SPEED_FREQ_HIGH;
    HAL_GPIO_Init(LED_RED_GPIO_Port, &GPIO_InitStruct);

    /*Configure GPIO pin : PD2 */
    GPIO_InitStruct.Pin = GPIO_PIN_2;
    GPIO_InitStruct.Mode = GPIO_MODE_ANALOG;
    GPIO_InitStruct.Pull = GPIO_NOPULL;
    HAL_GPIO_Init(GPIOD, &GPIO_InitStruct);

    /*Configure GPIO pin : BUTTON_LEFT_Pin */
    GPIO_InitStruct.Pin = BUTTON_LEFT_Pin;
    GPIO_InitStruct.Mode = GPIO_MODE_IT_RISING_FALLING;
    GPIO_InitStruct.Pull = GPIO_PULLDOWN;
    HAL_GPIO_Init(BUTTON_LEFT_GPIO_Port, &GPIO_InitStruct);

    /*Configure GPIO pin : CC1101_G0_Pin */
    GPIO_InitStruct.Pin = CC1101_G0_Pin;
    GPIO_InitStruct.Mode = GPIO_MODE_INPUT;
    GPIO_InitStruct.Pull = GPIO_NOPULL;
    HAL_GPIO_Init(CC1101_G0_GPIO_Port, &GPIO_InitStruct);

    /* EXTI interrupt init*/
    HAL_NVIC_SetPriority(EXTI0_IRQn, 5, 0);
    HAL_NVIC_EnableIRQ(EXTI0_IRQn);

    HAL_NVIC_SetPriority(EXTI1_IRQn, 5, 0);
    HAL_NVIC_EnableIRQ(EXTI1_IRQn);

    HAL_NVIC_SetPriority(EXTI2_IRQn, 5, 0);
    HAL_NVIC_EnableIRQ(EXTI2_IRQn);

    HAL_NVIC_SetPriority(EXTI4_IRQn, 5, 0);
    HAL_NVIC_EnableIRQ(EXTI4_IRQn);

    HAL_NVIC_SetPriority(EXTI9_5_IRQn, 5, 0);
    HAL_NVIC_EnableIRQ(EXTI9_5_IRQn);

    HAL_NVIC_SetPriority(EXTI15_10_IRQn, 5, 0);
    HAL_NVIC_EnableIRQ(EXTI15_10_IRQn);
}

/* USER CODE BEGIN 4 */
void app();
/* USER CODE END 4 */

void StartDefaultTask(void const* argument) {
    /* init code for USB_DEVICE */
    MX_USB_DEVICE_Init();
    /* USER CODE BEGIN 5 */
    /* Infinite loop */
    app();

    for(;;) {
        osDelay(1);
    }
    /* USER CODE END 5 */
}

void Error_Handler(void) {
}

/************************ (C) COPYRIGHT STMicroelectronics *****END OF FILE****/
